# ESP32S31_RADIO register map
Vendor: Espressif; Series: ESP32-S31; File version: 3.52
Registers are 32-bit, read-write, no defined reset value unless marked. A register's access mark holds for its fields unless they carry their own. Offsets are from the block's base; [hi:lo] are bit positions.

## WIFI_MAC_COEX_RUNTIME — Runtime receive-beacon and individual-TWT COEX/PTI words recovered from five complete hal_coex.o leaves. Register addresses, masks and RMW order are exact; fields whose electrical meaning is not established retain UNKNOWN names.
Base 0x2010D89C
0x00 CLEAR_REQUEST — Project-assigned name. Complete hal_clear_rx_beacon_pti sets bit zero through a fresh-read RMW. Complete hal_clr_itwt_pti sets the input-selected bit through the same word; the accepted index domain and remaining bit identities are not inferred.
  [31:0] BITS_0_31_OPAQUE — Opaque: meaning not established.
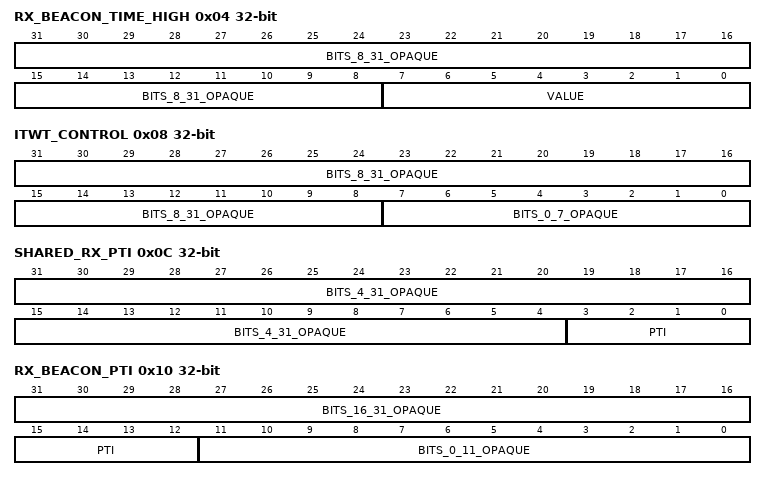
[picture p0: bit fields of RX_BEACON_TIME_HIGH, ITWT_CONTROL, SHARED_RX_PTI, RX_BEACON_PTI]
0x04 RX_BEACON_TIME_HIGH — Project-assigned name. Complete hal_set_rx_beacon_time replaces the low byte from bits 15:8 of its second argument after updating WIFI_MAC_RTC_TIMER_UPDATE.RX_BEACON_TIME_LOW.
  [31:8] BITS_8_31_OPAQUE — Opaque: meaning not established. Observed source use; the individual hardware meaning is unknown.
  [7:0] VALUE — Project-assigned name.
0x08 ITWT_CONTROL — Project-assigned name. Complete hal_set_itwt_pti clears the low byte and then writes seqz(argument zero) into bit zero. The remaining low-byte semantics are unknown.
  [31:8] BITS_8_31_OPAQUE — Opaque: meaning not established. Observed source use; the individual hardware meaning is unknown.
  [7:0] BITS_0_7_OPAQUE — Opaque: meaning not established.
0x0C SHARED_RX_PTI — Project-assigned name. Shared receive PTI word updated from the second argument by complete hal_set_rx_beacon_pti and hal_set_itwt_pti. Both leaves preserve bits 31:4 and replace only bits 3:0.
  [31:4] BITS_4_31_OPAQUE — Opaque: meaning not established. Observed source use; the individual hardware meaning is unknown.
  [3:0] PTI — Project-assigned name.
0x10 RX_BEACON_PTI — Project-assigned name. Complete hal_set_rx_beacon_pti replaces bits 15:12 from the low nibble of its first argument.
  [31:16] BITS_16_31_OPAQUE — Opaque: meaning not established. Observed source use; the individual hardware meaning is unknown.
  [15:12] PTI — Project-assigned name.
  [11:0] BITS_0_11_OPAQUE — Opaque: meaning not established. Observed source use; the individual hardware meaning is unknown.

## WIFI_MAC_COLD_HANDSHAKE — Cold MAC initialization request/ready handshake and the adjacent two WDEV timer targets recovered from complete ROM leaves.
Base 0x20104DE0
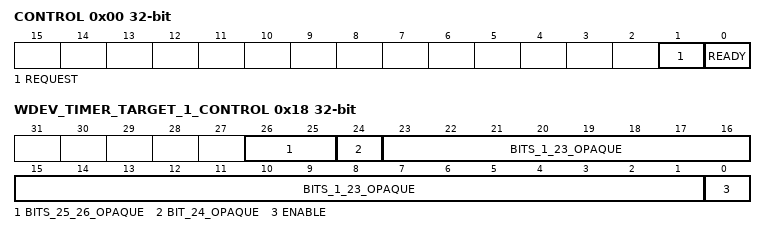
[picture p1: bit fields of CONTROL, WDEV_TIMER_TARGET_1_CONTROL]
0x00 CONTROL — Project-assigned name. Software sets REQUEST with a fresh-read RMW, then polls READY before touching the remaining MAC state.
  [1] REQUEST — Project-assigned name. Set before the READY polling loop.
  [0] READY ro — Project-assigned name. Polled until asserted after REQUEST.
0x10 WDEV_TIMER_TARGET_0_CONTROL — Project-assigned name. libpp[hal_tsf.o]::hal_wdev_timer_target_enable selects timer zero with argument zero and replaces enable bit zero.
  [0] ENABLE — Project-assigned name.
0x14 WDEV_TIMER_TARGET_0_VALUE wo — Project-assigned name. libpp[hal_tsf.o]::hal_wdev_timer_set_target selects timer zero with argument zero and writes the supplied 32-bit target.
  [31:0] VALUE — Project-assigned name.
0x18 WDEV_TIMER_TARGET_1_CONTROL — Project-assigned name. libpp[hal_tsf.o]::hal_wdev_timer_target_enable selects timer one with argument one and replaces enable bit zero.
  [26:25] BITS_25_26_OPAQUE — Opaque: meaning not established. Observed source use; the individual hardware meaning is unknown.
  [24] BIT_24_OPAQUE — Opaque: meaning not established. Observed source use; the individual hardware meaning is unknown.
  [23:1] BITS_1_23_OPAQUE — Opaque: meaning not established. Observed source use; the individual hardware meaning is unknown.
  [0] ENABLE — Project-assigned name.
0x1C WDEV_TIMER_TARGET_1_VALUE wo — Project-assigned name. libpp[hal_tsf.o]::hal_wdev_timer_set_target selects timer one with argument one and writes the supplied 32-bit target.
  [31:0] VALUE — Project-assigned name.
